# XHSC_HC32A052 register map
Vendor: XHSC Co.Ltd; Series: ARMCM4; File version: 1.2
CPU: CM0 r0p0, little endian, no MPU, no FPU, 3 interrupt priority bits
Registers are 32-bit, read-write, reset 0x0 unless marked. A register's access mark holds for its fields unless they carry their own. Offsets are from the block's base; [hi:lo] are bit positions; {n}, {i} and the like mark numbered series.

## BTIM0 — desc BTIM
Base 0x40001800
Same registers: BTIM1 0x40001900, BTIM2 0x40001A00
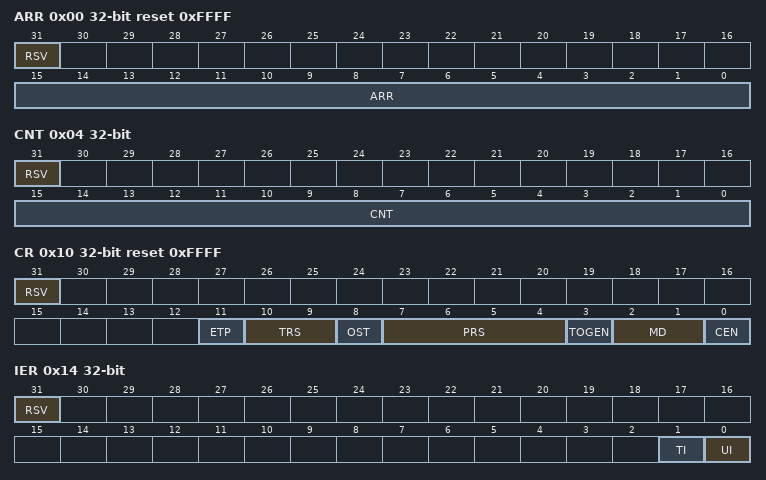
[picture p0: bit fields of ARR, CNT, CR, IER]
0x00 ARR reset 0xFFFF (reset mask 0xFFFF)
  [31] RSV, [15:0] ARR
0x04 CNT (reset mask 0xFFFF)
  [31] RSV, [15:0] CNT
0x10 CR reset 0xFFFF (reset mask 0xFFF)
  [31] RSV, [11] ETP, [10:9] TRS, [8] OST, [7:4] PRS, [3] TOGEN, [2:1] MD, [0] CEN
0x14 IER (reset mask 0x3)
  [31] RSV, [1] TI, [0] UI
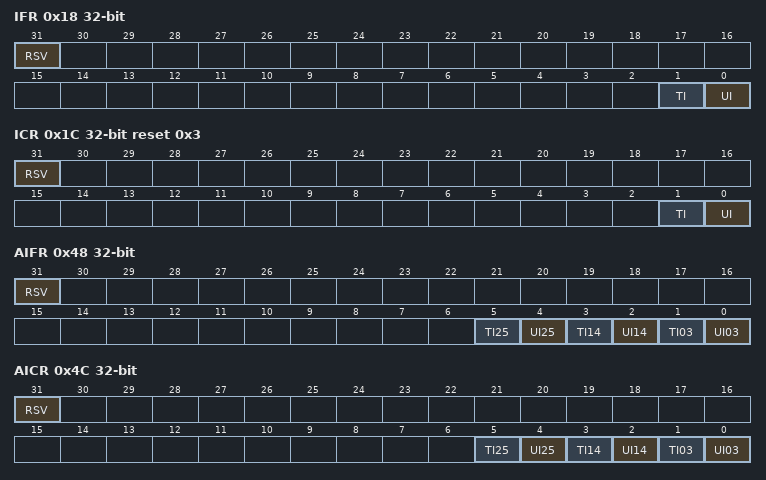
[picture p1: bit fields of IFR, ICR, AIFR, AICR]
0x18 IFR ro (reset mask 0x3)
  [31] RSV, [1] TI, [0] UI
0x1C ICR reset 0x3 (reset mask 0x3)
  [31] RSV, [1] TI, [0] UI
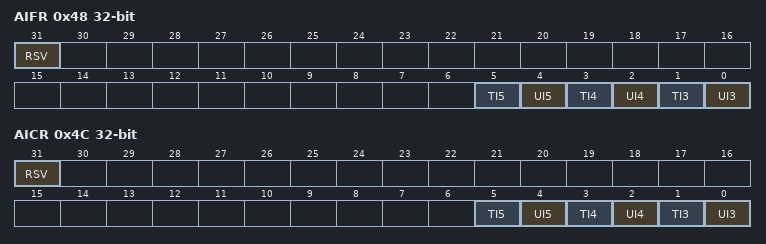
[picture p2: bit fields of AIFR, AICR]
0x48 AIFR ro (reset mask 0x3F)
  [31] RSV, [5] TI25, [4] UI25, [3] TI14, [2] UI14, [1] TI03, [0] UI03
0x4C AICR (reset mask 0xF)
  [31] RSV, [5] TI25, [4] UI25, [3] TI14, [2] UI14, [1] TI03, [0] UI03

## BTIM3 — desc BTIM
Base 0x40001C00
Same registers: BTIM4 0x40001D00, BTIM5 0x40001E00
Registers as BTIM0; these are added or differ:
0x48 AIFR ro (reset mask 0x3F)
  [31] RSV, [5] TI5, [4] UI5, [3] TI4, [2] UI4, [1] TI3, [0] UI3
0x4C AICR (reset mask 0xF)
  [31] RSV, [5] TI5, [4] UI5, [3] TI4, [2] UI4, [1] TI3, [0] UI3

## CAN
Base 0x40030000
{0x0+4i} RBUF{i} ro (i=0..3)
{0x50+4i} TBUF{i} (i=0..3)
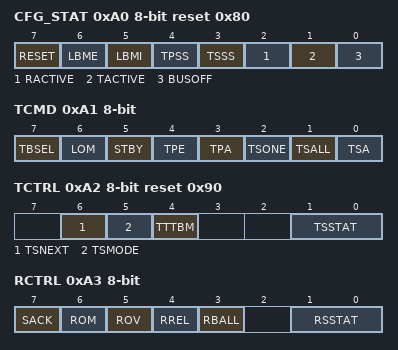
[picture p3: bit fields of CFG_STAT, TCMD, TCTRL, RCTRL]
0xA0 CFG_STAT 8-bit reset 0x80
  [7] RESET, [6] LBME, [5] LBMI, [4] TPSS, [3] TSSS, [2] RACTIVE ro, [1] TACTIVE ro, [0] BUSOFF
0xA1 TCMD 8-bit
  [7] TBSEL, [6] LOM, [5] STBY, [4] TPE, [3] TPA, [2] TSONE, [1] TSALL, [0] TSA
0xA2 TCTRL 8-bit reset 0x90
  [6] TSNEXT, [5] TSMODE, [4] TTTBM, [1:0] TSSTAT ro
0xA3 RCTRL 8-bit
  [7] SACK, [6] ROM, [5] ROV ro, [4] RREL, [3] RBALL, [1:0] RSSTAT ro
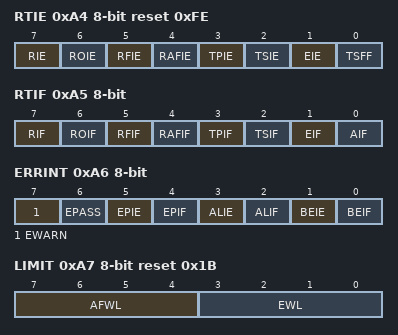
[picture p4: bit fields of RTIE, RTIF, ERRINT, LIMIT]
0xA4 RTIE 8-bit reset 0xFE
  [7] RIE, [6] ROIE, [5] RFIE, [4] RAFIE, [3] TPIE, [2] TSIE, [1] EIE, [0] TSFF ro
0xA5 RTIF 8-bit
  [7] RIF, [6] ROIF, [5] RFIF, [4] RAFIF, [3] TPIF, [2] TSIF, [1] EIF, [0] AIF
0xA6 ERRINT 8-bit
  [7] EWARN ro, [6] EPASS ro, [5] EPIE, [4] EPIF, [3] ALIE, [2] ALIF, [1] BEIE, [0] BEIF
0xA7 LIMIT 8-bit reset 0x1B
  [7:4] AFWL, [3:0] EWL
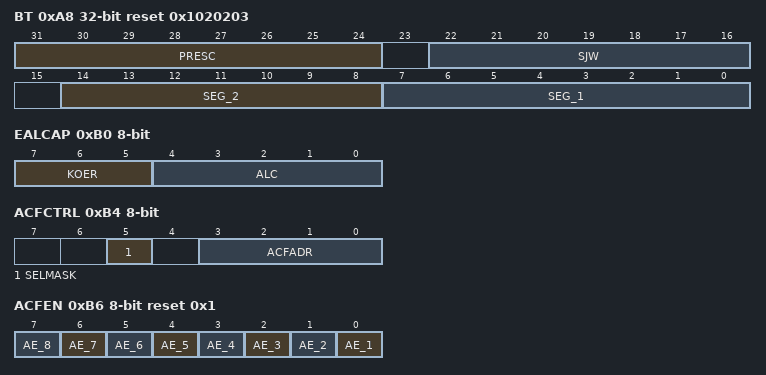
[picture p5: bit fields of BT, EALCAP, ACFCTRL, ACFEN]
0xA8 BT reset 0x1020203
  [31:24] PRESC, [22:16] SJW, [14:8] SEG_2, [7:0] SEG_1
0xB0 EALCAP 8-bit ro
  [7:5] KOER, [4:0] ALC
0xB2 RECNT 8-bit
0xB3 TECNT 8-bit
0xB4 ACFCTRL 8-bit
  [5] SELMASK, [3:0] ACFADR
0xB6 ACFEN 8-bit reset 0x1
  [n-1] AE_{n} (n=1..8)
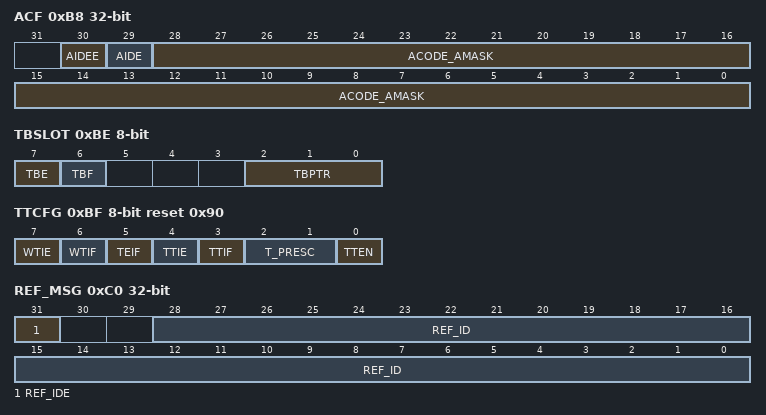
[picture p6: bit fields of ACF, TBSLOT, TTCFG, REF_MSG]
0xB8 ACF
  [30] AIDEE, [29] AIDE, [28:0] ACODE_AMASK
0xBE TBSLOT 8-bit
  [7] TBE, [6] TBF, [2:0] TBPTR
0xBF TTCFG 8-bit reset 0x90
  [7] WTIE, [6] WTIF, [5] TEIF, [4] TTIE, [3] TTIF, [2:1] T_PRESC, [0] TTEN
0xC0 REF_MSG
  [31] REF_IDE, [28:0] REF_ID
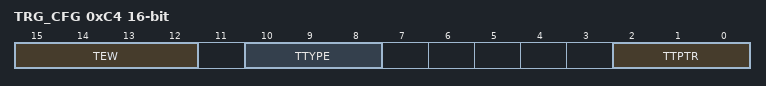
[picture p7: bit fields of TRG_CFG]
0xC4 TRG_CFG 16-bit
  [15:12] TEW, [10:8] TTYPE, [2:0] TTPTR
0xC6 TT_TRIG 16-bit
0xC8 TT_WTRIG 16-bit reset 0xFFFF

## CRC
Base 0x40020800
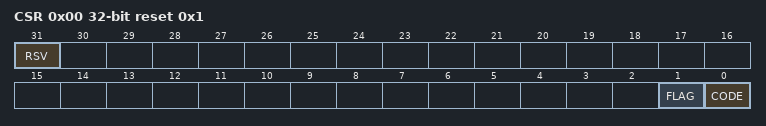
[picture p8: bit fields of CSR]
0x00 CSR reset 0x1 (reset mask 0x3)
  [31] RSV ro, [1] FLAG ro, [0] CODE
0x04 RESULT
0x80 DATA wo

## CTRIM
Base 0x40005000
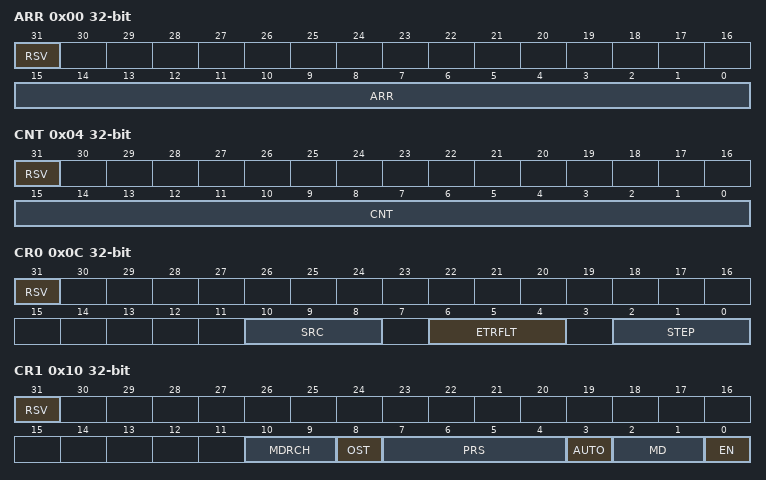
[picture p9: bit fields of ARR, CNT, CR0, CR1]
0x00 ARR (reset mask 0xFFFF)
  [31] RSV, [15:0] ARR
0x04 CNT ro (reset mask 0xFFFF)
  [31] RSV, [15:0] CNT
0x0C CR0 (reset mask 0x777)
  [31] RSV, [10:8] SRC, [6:4] ETRFLT, [2:0] STEP
0x10 CR1 (reset mask 0x7FF)
  [31] RSV, [10:9] MDRCH, [8] OST, [7:4] PRS, [3] AUTO, [2:1] MD, [0] EN
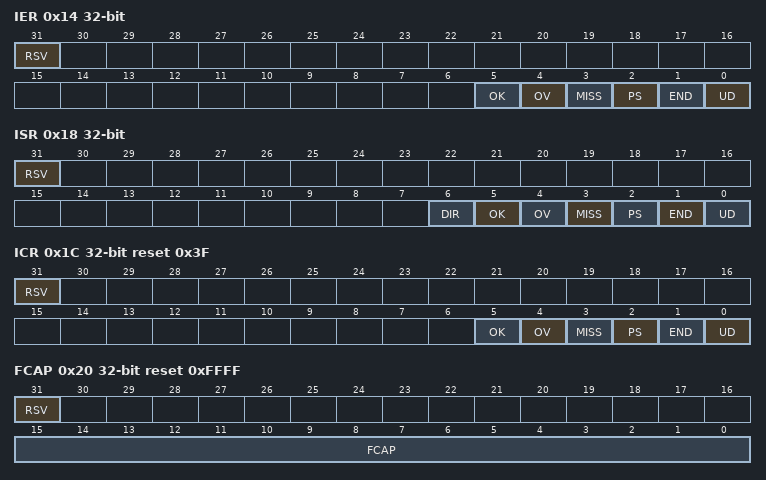
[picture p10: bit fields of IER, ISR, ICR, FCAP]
0x14 IER (reset mask 0x3F)
  [31] RSV, [5] OK, [4] OV, [3] MISS, [2] PS, [1] END, [0] UD
0x18 ISR ro (reset mask 0x7F)
  [31] RSV, [6] DIR, [5] OK, [4] OV, [3] MISS, [2] PS, [1] END, [0] UD
0x1C ICR reset 0x3F (reset mask 0x3F)
  [31] RSV, [5] OK, [4] OV, [3] MISS, [2] PS, [1] END, [0] UD
0x20 FCAP ro reset 0xFFFF (reset mask 0xFFFF)
  [31] RSV, [15:0] FCAP
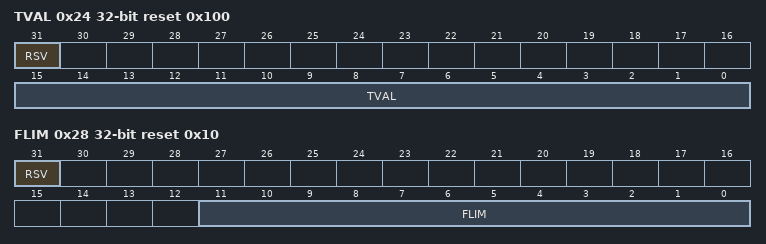
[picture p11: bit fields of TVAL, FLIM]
0x24 TVAL ro reset 0x100 (reset mask 0xFFFF)
  [31] RSV, [15:0] TVAL
0x28 FLIM reset 0x10 (reset mask 0xFFF)
  [31] RSV, [11:0] FLIM

## DMAC
Base 0x40021000
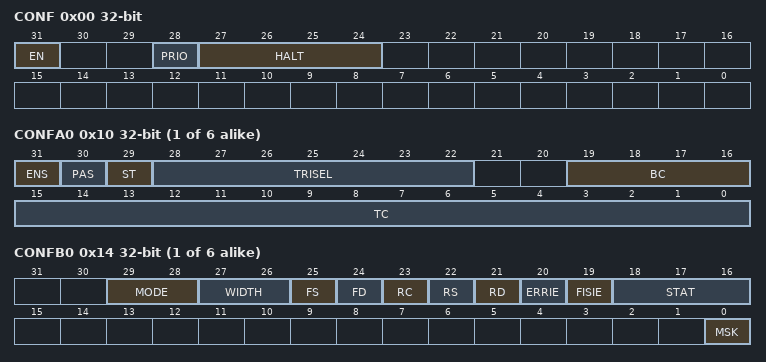
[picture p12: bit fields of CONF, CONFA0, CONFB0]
0x00 CONF
  [31] EN, [28] PRIO, [27:24] HALT
{0x10+0x10*i} CONFA{i} (i=0..5)
  [31] ENS, [30] PAS, [29] ST, [28:22] TRISEL, [19:16] BC, [15:0] TC
{0x14+0x10*i} CONFB{i} (i=0..5)
  [29:28] MODE, [27:26] WIDTH, [25] FS, [24] FD, [23] RC, [22] RS, [21] RD, [20] ERRIE, [19] FISIE, [18:16] STAT, [0] MSK
{0x18+0x10*i} SRCADR{i} (i=0..5)
  [31:0] SRCADR
{0x1C+0x10*i} DSTADR{i} (i=0..5)
  [31:0] DSTADR
